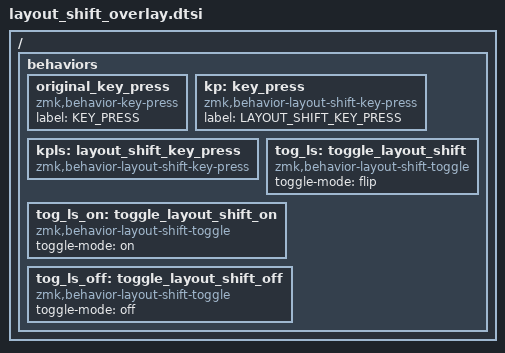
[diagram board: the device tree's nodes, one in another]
// Layout Shift Overlay - Replaces &kp behavior with custom implementation
// This file should be included in keyboard config to override &kp behavior

/ {
    behaviors {
        // Keep the original key_press behavior for ZMK core components
        original_key_press: original_key_press {
            compatible = "zmk,behavior-key-press";
            #binding-cells = <1>;
            label = "KEY_PRESS";
        };

        // Override the existing &kp behavior to use our custom implementation
        kp: key_press {
            compatible = "zmk,behavior-layout-shift-key-press";
            #binding-cells = <1>;
            label = "LAYOUT_SHIFT_KEY_PRESS";
        };

        // Add the &kpls behavior alias
        /omit-if-no-ref/ kpls: layout_shift_key_press {
            compatible = "zmk,behavior-layout-shift-key-press";
            #binding-cells = <1>;
        };

        // Layout shift toggle behaviors
        /omit-if-no-ref/ tog_ls: toggle_layout_shift {
            compatible = "zmk,behavior-layout-shift-toggle";
            #binding-cells = <0>;
            toggle-mode = "flip";
        };

        /omit-if-no-ref/ tog_ls_on: toggle_layout_shift_on {
            compatible = "zmk,behavior-layout-shift-toggle";
            #binding-cells = <0>;
            toggle-mode = "on";
        };

        /omit-if-no-ref/ tog_ls_off: toggle_layout_shift_off {
            compatible = "zmk,behavior-layout-shift-toggle";
            #binding-cells = <0>;
            toggle-mode = "off";
        };
    };
};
